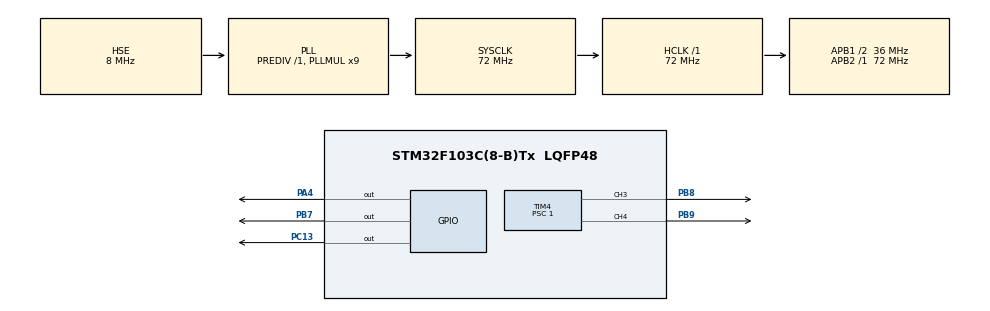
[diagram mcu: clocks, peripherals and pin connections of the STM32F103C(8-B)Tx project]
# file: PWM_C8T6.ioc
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Mcu.Family=STM32F1
Mcu.Name=STM32F103C(8-B)Tx
Mcu.Package=LQFP48
NVIC.PriorityGroup=NVIC_PRIORITYGROUP_4
PA13.Mode=Serial_Wire
PA13.Signal=SYS_JTMS-SWDIO
PA14.Mode=Serial_Wire
PA14.Signal=SYS_JTCK-SWCLK
PA4.Signal=GPIO_Output
PB7.Signal=GPIO_Output
PB8.Signal=S_TIM4_CH3
PB9.Signal=S_TIM4_CH4
PC13-TAMPER-RTC.Signal=GPIO_Output
PD0-OSC_IN.Mode=HSE-External-Oscillator
PD0-OSC_IN.Signal=RCC_OSC_IN
PD1-OSC_OUT.Mode=HSE-External-Oscillator
PD1-OSC_OUT.Signal=RCC_OSC_OUT
ProjectManager.HeapSize=0x200
ProjectManager.StackSize=0x400
ProjectManager.TargetToolchain=MDK-ARM V5.27
RCC.AHBFreq_Value=72000000
RCC.APB1CLKDivider=RCC_HCLK_DIV2
RCC.APB1Freq_Value=36000000
RCC.APB1TimFreq_Value=72000000
RCC.APB2Freq_Value=72000000
RCC.APB2TimFreq_Value=72000000
RCC.HCLKFreq_Value=72000000
RCC.PLLMUL=RCC_PLL_MUL9
RCC.PLLSourceVirtual=RCC_PLLSOURCE_HSE
RCC.SYSCLKFreq_VALUE=72000000
RCC.SYSCLKSource=RCC_SYSCLKSOURCE_PLLCLK
RCC.USBFreq_Value=72000000
SH.S_TIM4_CH3.0=TIM4_CH3,PWM Generation3 CH3
SH.S_TIM4_CH4.0=TIM4_CH4,PWM Generation4 CH4
TIM4.AutoReloadPreload=TIM_AUTORELOAD_PRELOAD_ENABLE
TIM4.Channel-PWM\ Generation3\ CH3=TIM_CHANNEL_3
TIM4.Channel-PWM\ Generation4\ CH4=TIM_CHANNEL_4
TIM4.OCMode_PWM-PWM\ Generation3\ CH3=TIM_OCMODE_PWM2
TIM4.OCMode_PWM-PWM\ Generation4\ CH4=TIM_OCMODE_PWM2
TIM4.Period=3599
TIM4.Prescaler=1
board=custom

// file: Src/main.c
/* USER CODE BEGIN Header */
/**
  ******************************************************************************
  * @file           : main.c
  * @brief          : Main program body
  ******************************************************************************
  * @attention
  *
  * <h2><center>&copy; Copyright (c) 2023 STMicroelectronics.
  * All rights reserved.</center></h2>
  *
  * This software component is licensed by ST under BSD 3-Clause license,
  * the "License"; You may not use this file except in compliance with the
  * License. You may obtain a copy of the License at:
  *                        opensource.org/licenses/BSD-3-Clause
  *
  ******************************************************************************
  */
/* USER CODE END Header */

#include "main.h"
#include "tim.h"
#include "gpio.h"

/* USER CODE BEGIN Includes */
#include "motor.h"
/* USER CODE END Includes */

void SystemClock_Config(void);

int main(void)
{

  /* MCU Configuration--------------------------------------------------------*/

  /* Reset of all peripherals, Initializes the Flash interface and the Systick. */
  HAL_Init();

  /* Configure the system clock */
  SystemClock_Config();

  /* Initialize all configured peripherals */
  MX_GPIO_Init();
  MX_TIM4_Init();
  /* USER CODE BEGIN 2 */
	HAL_TIM_PWM_Start(&htim4,TIM_CHANNEL_3);
	HAL_TIM_PWM_Start(&htim4,TIM_CHANNEL_4);
  /* USER CODE END 2 */

  /* Infinite loop */
  while (1)
  {

    /* USER CODE BEGIN 3 */
//		back(70,1000);
		brake(500);
		forward(70,1000);
//		brake(500);
//		turn_left(70,1000);
		brake(500);
//		turn_right(70,1000);
//		brake(100);

		brake(500);
//		spin_left(70,1000);
		brake(500);
		spin_right(70,1000);
//		brake(500);

//		HAL_Delay(200);
  }
  /* USER CODE END 3 */
}

void SystemClock_Config(void)
{
  RCC_OscInitTypeDef RCC_OscInitStruct = {0};
  RCC_ClkInitTypeDef RCC_ClkInitStruct = {0};

  /** Initializes the CPU, AHB and APB busses clocks
  */
  RCC_OscInitStruct.OscillatorType = RCC_OSCILLATORTYPE_HSE;
  RCC_OscInitStruct.HSEState = RCC_HSE_ON;
  RCC_OscInitStruct.HSEPredivValue = RCC_HSE_PREDIV_DIV1;
  RCC_OscInitStruct.HSIState = RCC_HSI_ON;
  RCC_OscInitStruct.PLL.PLLState = RCC_PLL_ON;
  RCC_OscInitStruct.PLL.PLLSource = RCC_PLLSOURCE_HSE;
  RCC_OscInitStruct.PLL.PLLMUL = RCC_PLL_MUL9;
  if (HAL_RCC_OscConfig(&RCC_OscInitStruct) != HAL_OK)
  {
    Error_Handler();
  }
  /** Initializes the CPU, AHB and APB busses clocks
  */
  RCC_ClkInitStruct.ClockType = RCC_CLOCKTYPE_HCLK|RCC_CLOCKTYPE_SYSCLK
                              |RCC_CLOCKTYPE_PCLK1|RCC_CLOCKTYPE_PCLK2;
  RCC_ClkInitStruct.SYSCLKSource = RCC_SYSCLKSOURCE_PLLCLK;
  RCC_ClkInitStruct.AHBCLKDivider = RCC_SYSCLK_DIV1;
  RCC_ClkInitStruct.APB1CLKDivider = RCC_HCLK_DIV2;
  RCC_ClkInitStruct.APB2CLKDivider = RCC_HCLK_DIV1;

  if (HAL_RCC_ClockConfig(&RCC_ClkInitStruct, FLASH_LATENCY_2) != HAL_OK)
  {
    Error_Handler();
  }
}

void Error_Handler(void)
{
}

/************************ (C) COPYRIGHT STMicroelectronics *****END OF FILE****/
